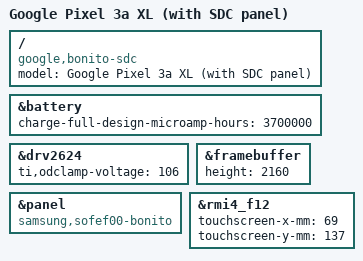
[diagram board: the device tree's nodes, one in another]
// SPDX-License-Identifier: GPL-2.0-only
/*
 * Device tree for Google Pixel 3a XL with the panel connected to the Samsung
 * Display Controller.
 *
 * Copyright (c) 2023, Richard Acayan. All rights reserved.
 */

/dts-v1/;

#include "sdm670-google-common.dtsi"

/ {
	model = "Google Pixel 3a XL (with SDC panel)";
	compatible = "google,bonito-sdc", "google,bonito", "qcom,sdm670";
};

&battery {
	charge-full-design-microamp-hours = <3700000>;
};

&drv2624 {
	ti,odclamp-voltage = <106>; /* 2.1 Vrms */
};

&framebuffer {
	height = <2160>;
};

&panel {
	compatible = "samsung,sofef00-bonito";
};

&rmi4_f12 {
	touchscreen-x-mm = <69>;
	touchscreen-y-mm = <137>;
};
